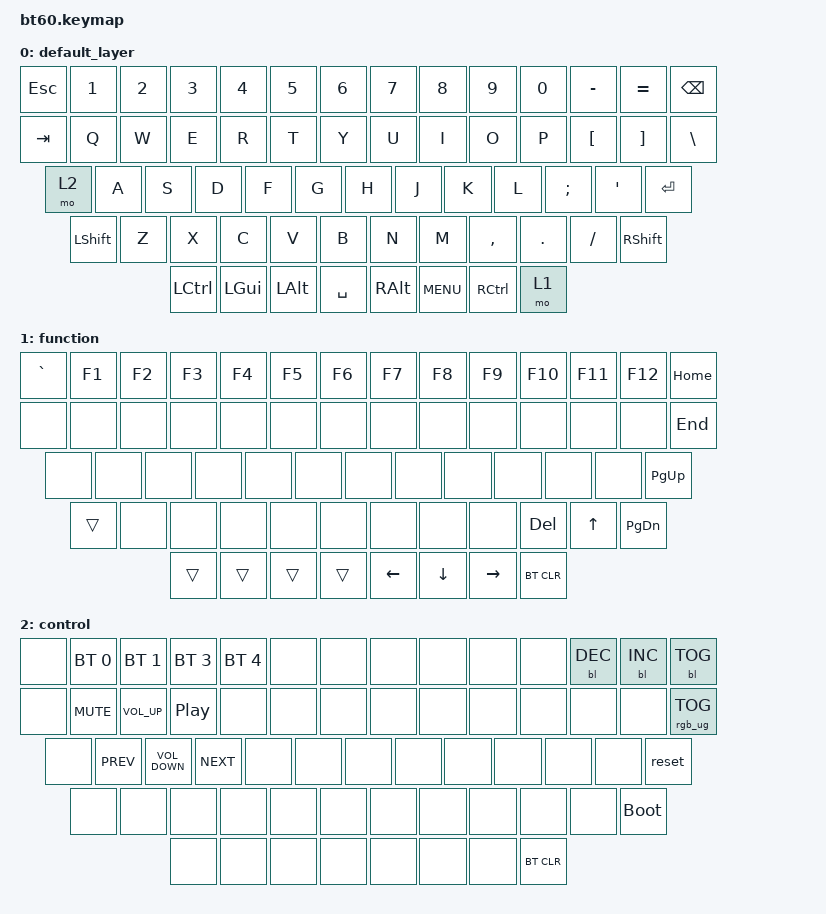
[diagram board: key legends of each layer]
#include <behaviors.dtsi>
#include <dt-bindings/zmk/keys.h>
#include <dt-bindings/zmk/bt.h>
#include <dt-bindings/zmk/rgb.h>
#include <dt-bindings/zmk/backlight.h>

/ {
	keymap {
		compatible = "zmk,keymap";

		default_layer {
				// ------------------------------------------------------------------------------------------
				// |  `  |  1  |  2  |  3  |  4  |  5  |  6  |  7  |  8  |  9  |  0  |  -  |  =  |   BKSP
				// | TAB  |  Q  |  W  |  E  |  R  |  T  |  Y  |  U  |  I  |  O  |  P  |  [  |  ]  |   |
				// |   2    |  A  |  S  |  D  |  F  |  G  |  H  |  J  |  K  |  L  |  ;  |  '  |     ENTER
				// |  SHIFT    |  Z  |  X  |  C  |  V  |  B  |  N  |  M  |  ,  |  .  | /   |      SHIFT
				// |  CTL  |  WIN  |  ALT  |            SPACE               | ALT | 1    |  MENU    |  CTRL
				// ------------------------------------------------------------------------------------------
			bindings = <

				&kp ESC &kp N1 &kp N2 &kp N3 &kp N4 &kp N5 &kp N6 &kp N7 &kp N8 &kp N9 &kp N0 &kp MINUS &kp EQUAL &kp BSPC
				&kp TAB &kp Q &kp W &kp E &kp R &kp T &kp Y &kp U &kp I &kp O &kp P &kp LBKT &kp RBKT &kp BSLH
				&mo 2 &kp A &kp S &kp D &kp F &kp G &kp H &kp J &kp K &kp L &kp SEMI &kp SQT &kp RET 
				&kp LSHFT &kp Z &kp X &kp C &kp V &kp B &kp N &kp M &kp COMMA &kp DOT &kp FSLH &kp RSHFT
				&kp LCTRL &kp LGUI &kp LALT &kp SPACE &kp RALT &kp K_MENU &kp RCTRL &mo 1
			>;
			sensor-bindings = <&inc_dec_kp C_VOL_UP C_VOL_DN>;
		};
		function {
			bindings = <
				&kp GRAVE
				&kp F1
				&kp F2
				&kp F3
				&kp F4
				&kp F5
				&kp F6
				&kp F7
				&kp F8
				&kp F9
				&kp F10
				&kp F11
				&kp F12
				&kp HOME
				&none
				&none
				&none
				&none
				&none
				&none
				&none
				&none
				&none
				&none
				&none
				&none
				&none
				&kp END
				&none
				&none
				&none
				&none
				&none
				&none
				&none
				&none
				&none
				&none
				&none
				&none
				&kp PG_UP
				&trans
				&none
				&none
				&none
				&none
				&none
				&none
				&none
				&none
				&kp DEL
				&kp UP
				&kp PG_DN
				&trans
				&trans
				&trans
				&trans
				&kp LEFT
				&kp DOWN
				&kp RIGHT
				&bt BT_CLR
			>;
			sensor-bindings = <&inc_dec_kp C_VOL_UP C_VOL_DN>;
		};
		control {
			bindings = <
				&none
				&bt BT_SEL 0
				&bt BT_SEL 1
				&bt BT_SEL 3
				&bt BT_SEL 4
				&none
				&none
				&none
				&none
				&none
				&none
				&bl BL_DEC
				&bl BL_INC
				&bl BL_TOG
				&none
				&kp C_MUTE
				&kp C_VOLUME_UP
				&kp C_PLAY_PAUSE
				&none
				&none
				&none
				&none
				&none
				&none
				&none
				&none
				&none
				&rgb_ug RGB_TOG
				&none
				&kp C_PREV
				&kp C_VOLUME_DOWN
				&kp C_NEXT
				&none
				&none
				&none
				&none
				&none
				&none
				&none
				&none
				&reset
				&none
				&none
				&none
				&none
				&none
				&none
				&none
				&none
				&none
				&none
				&none
				&bootloader
				&none
				&none
				&none
				&none
				&none
				&none
				&none
				&bt BT_CLR
			>;
			sensor-bindings = <&inc_dec_kp C_VOL_UP C_VOL_DN>;
		};
	};
};
